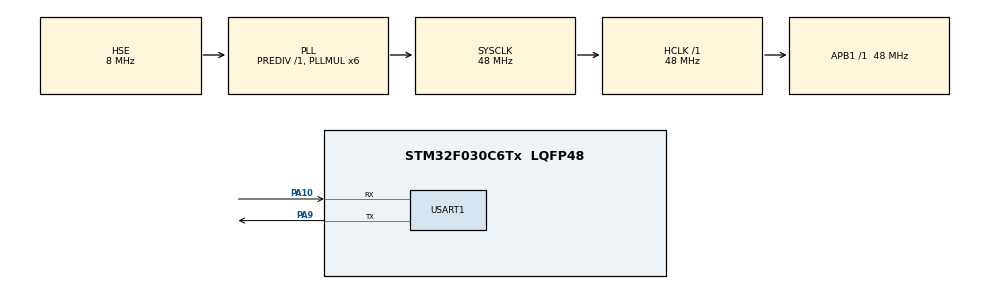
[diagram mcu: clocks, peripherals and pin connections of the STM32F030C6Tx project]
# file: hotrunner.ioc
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Mcu.Family=STM32F0
Mcu.Name=STM32F030C6Tx
Mcu.Package=LQFP48
PA10.Mode=Asynchronous
PA10.Signal=USART1_RX
PA13.Mode=Serial_Wire
PA13.Signal=SYS_SWDIO
PA14.Mode=Serial_Wire
PA14.Signal=SYS_SWCLK
PA9.Mode=Asynchronous
PA9.Signal=USART1_TX
PF0-OSC_IN.Mode=HSE-External-Oscillator
PF0-OSC_IN.Signal=RCC_OSC_IN
PF1-OSC_OUT.Mode=HSE-External-Oscillator
PF1-OSC_OUT.Signal=RCC_OSC_OUT
ProjectManager.HeapSize=0x200
ProjectManager.StackSize=0x400
ProjectManager.TargetToolchain=MDK-ARM V5
RCC.AHBFreq_Value=48000000
RCC.APB1Freq_Value=48000000
RCC.APB1TimFreq_Value=48000000
RCC.HCLKFreq_Value=48000000
RCC.PLLMUL=RCC_PLL_MUL6
RCC.PLLSourceVirtual=RCC_PLLSOURCE_HSE
RCC.SYSCLKFreq_VALUE=48000000
RCC.SYSCLKSource=RCC_SYSCLKSOURCE_PLLCLK
USART1.VirtualMode-Asynchronous=VM_ASYNC
board=custom

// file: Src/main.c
/* USER CODE BEGIN Header */
/**
  ******************************************************************************
  * @file           : main.c
  * @brief          : Main program body
  ******************************************************************************
  * @attention
  *
  * <h2><center>&copy; Copyright (c) 2020 STMicroelectronics.
  * All rights reserved.</center></h2>
  *
  * This software component is licensed by ST under BSD 3-Clause license,
  * the "License"; You may not use this file except in compliance with the
  * License. You may obtain a copy of the License at:
  *                        opensource.org/licenses/BSD-3-Clause
  *
  ******************************************************************************
  */
/* USER CODE END Header */

#include "main.h"
#include "usart.h"
#include "gpio.h"

/* USER CODE BEGIN Includes */
#include "b_os.h"
/* USER CODE END Includes */

void SystemClock_Config(void);

int main(void)
{

  /* MCU Configuration--------------------------------------------------------*/

  /* Reset of all peripherals, Initializes the Flash interface and the Systick. */
  HAL_Init();

  /* Configure the system clock */
  SystemClock_Config();

  /* Initialize all configured peripherals */
  MX_GPIO_Init();
  MX_USART1_UART_Init();

  /* Infinite loop */
  /* USER CODE BEGIN WHILE */
	bInit();
	b_log("b_log\r\n");
	b_log_i("b_log_i\r\n");
	b_log_w("b_log_w\r\n");
	b_log_e("b_log_e\r\n");

	while (1)
	{
			bExec();
    /* USER CODE END WHILE */

	}
}

void SystemClock_Config(void)
{
  RCC_OscInitTypeDef RCC_OscInitStruct = {0};
  RCC_ClkInitTypeDef RCC_ClkInitStruct = {0};
  RCC_PeriphCLKInitTypeDef PeriphClkInit = {0};

  /** Initializes the CPU, AHB and APB busses clocks
  */
  RCC_OscInitStruct.OscillatorType = RCC_OSCILLATORTYPE_HSE;
  RCC_OscInitStruct.HSEState = RCC_HSE_ON;
  RCC_OscInitStruct.PLL.PLLState = RCC_PLL_ON;
  RCC_OscInitStruct.PLL.PLLSource = RCC_PLLSOURCE_HSE;
  RCC_OscInitStruct.PLL.PLLMUL = RCC_PLL_MUL6;
  RCC_OscInitStruct.PLL.PREDIV = RCC_PREDIV_DIV1;
  if (HAL_RCC_OscConfig(&RCC_OscInitStruct) != HAL_OK)
  {
    Error_Handler();
  }
  /** Initializes the CPU, AHB and APB busses clocks
  */
  RCC_ClkInitStruct.ClockType = RCC_CLOCKTYPE_HCLK|RCC_CLOCKTYPE_SYSCLK
                              |RCC_CLOCKTYPE_PCLK1;
  RCC_ClkInitStruct.SYSCLKSource = RCC_SYSCLKSOURCE_PLLCLK;
  RCC_ClkInitStruct.AHBCLKDivider = RCC_SYSCLK_DIV1;
  RCC_ClkInitStruct.APB1CLKDivider = RCC_HCLK_DIV1;

  if (HAL_RCC_ClockConfig(&RCC_ClkInitStruct, FLASH_LATENCY_1) != HAL_OK)
  {
    Error_Handler();
  }
  PeriphClkInit.PeriphClockSelection = RCC_PERIPHCLK_USART1;
  PeriphClkInit.Usart1ClockSelection = RCC_USART1CLKSOURCE_PCLK1;
  if (HAL_RCCEx_PeriphCLKConfig(&PeriphClkInit) != HAL_OK)
  {
    Error_Handler();
  }
}

void Error_Handler(void)
{
}

/************************ (C) COPYRIGHT STMicroelectronics *****END OF FILE****/
